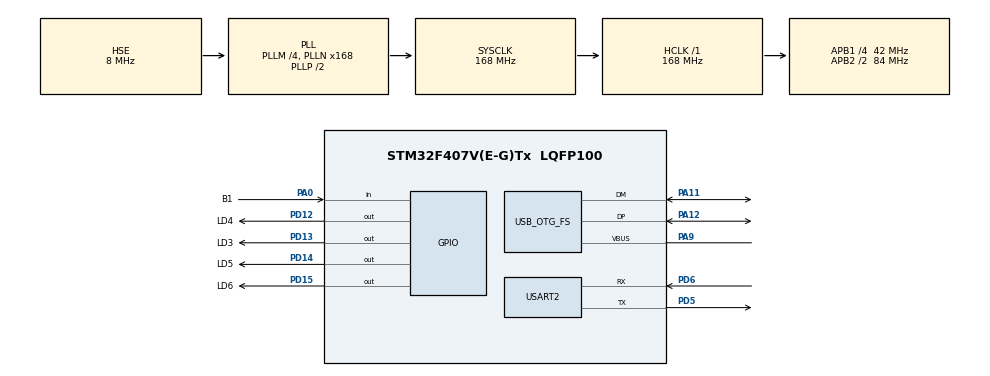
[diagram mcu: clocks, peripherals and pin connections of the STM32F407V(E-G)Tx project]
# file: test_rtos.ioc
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FREERTOS.Tasks01=defaultTask,0,128,StartDefaultTask,Default
Mcu.Family=STM32F4
Mcu.Name=STM32F407V(E-G)Tx
Mcu.Package=LQFP100
NVIC.OTG_FS_IRQn=true\:5\:0\:false\:false\:true\:true
NVIC.PriorityGroup=NVIC_PRIORITYGROUP_4
NVIC.TIM6_DAC_IRQn=true\:0\:0\:false\:false\:true\:false
NVIC.TimeBase=TIM6_DAC_IRQn
NVIC.TimeBaseIP=TIM6
PA0-WKUP.GPIO_Label=B1
PA0-WKUP.Signal=GPIO_Input
PA11.Mode=Device_Only
PA11.Signal=USB_OTG_FS_DM
PA12.Mode=Device_Only
PA12.Signal=USB_OTG_FS_DP
PA9.Mode=Activate_VBUS
PA9.Signal=USB_OTG_FS_VBUS
PD12.GPIO_Label=LD4
PD12.Signal=GPIO_Output
PD13.GPIO_Label=LD3
PD13.Signal=GPIO_Output
PD14.GPIO_Label=LD5
PD14.Signal=GPIO_Output
PD15.GPIO_Label=LD6
PD15.Signal=GPIO_Output
PD5.Mode=Asynchronous
PD5.Signal=USART2_TX
PD6.Mode=Asynchronous
PD6.Signal=USART2_RX
PH0-OSC_IN.Mode=HSE-External-Oscillator
PH0-OSC_IN.Signal=RCC_OSC_IN
PH1-OSC_OUT.Mode=HSE-External-Oscillator
PH1-OSC_OUT.Signal=RCC_OSC_OUT
ProjectManager.HeapSize=0x200
ProjectManager.StackSize=0x400
ProjectManager.TargetToolchain=SW4STM32
RCC.48MHZClocksFreq_Value=48000000
RCC.AHBFreq_Value=168000000
RCC.APB1CLKDivider=RCC_HCLK_DIV4
RCC.APB1Freq_Value=42000000
RCC.APB1TimFreq_Value=84000000
RCC.APB2CLKDivider=RCC_HCLK_DIV2
RCC.APB2Freq_Value=84000000
RCC.APB2TimFreq_Value=168000000
RCC.CortexFreq_Value=168000000
RCC.HCLKFreq_Value=168000000
RCC.HSE_VALUE=8000000
RCC.HSI_VALUE=16000000
RCC.LSE_VALUE=32768
RCC.PLLM=4
RCC.PLLN=168
RCC.PLLQ=7
RCC.SYSCLKFreq_VALUE=168000000
RCC.SYSCLKSource=RCC_SYSCLKSOURCE_PLLCLK
RCC.VCOOutputFreq_Value=336000000
USB_DEVICE.CLASS_NAME-CDC_FS=CDC
USB_DEVICE.CLASS_NAME_FS=CDC
USB_DEVICE.USBD_HandleTypeDef-CDC_FS=hUsbDeviceFS
USB_DEVICE.VirtualMode-CDC_FS=Cdc
USB_DEVICE.VirtualModeFS=Cdc_FS
USB_OTG_FS.VirtualMode=Device_Only
VP_FREERTOS_VS_ENABLE.Mode=Enabled
VP_SYS_VS_tim6.Mode=TIM6
VP_USB_DEVICE_VS_USB_DEVICE_CDC_FS.Mode=CDC_FS
board=test_rtos

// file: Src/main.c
/**
  ******************************************************************************
  * File Name          : main.c
  * Description        : Main program body
  ******************************************************************************
  *
  * Copyright (c) 2017 STMicroelectronics International N.V.
  * All rights reserved.
  *
  * Redistribution and use in source and binary forms, with or without
  * modification, are permitted, provided that the following conditions are met:
  *
  * 1. Redistribution of source code must retain the above copyright notice,
  *    this list of conditions and the following disclaimer.
  * 2. Redistributions in binary form must reproduce the above copyright notice,
  *    this list of conditions and the following disclaimer in the documentation
  *    and/or other materials provided with the distribution.
  * 3. Neither the name of STMicroelectronics nor the names of other
  *    contributors to this software may be used to endorse or promote products
  *    derived from this software without specific written permission.
  * 4. This software, including modifications and/or derivative works of this
  *    software, must execute solely and exclusively on microcontroller or
  *    microprocessor devices manufactured by or for STMicroelectronics.
  * 5. Redistribution and use of this software other than as permitted under
  *    this license is void and will automatically terminate your rights under
  *    this license.
  *
  * THIS SOFTWARE IS PROVIDED BY STMICROELECTRONICS AND CONTRIBUTORS "AS IS"
  * AND ANY EXPRESS, IMPLIED OR STATUTORY WARRANTIES, INCLUDING, BUT NOT
  * LIMITED TO, THE IMPLIED WARRANTIES OF MERCHANTABILITY, FITNESS FOR A
  * PARTICULAR PURPOSE AND NON-INFRINGEMENT OF THIRD PARTY INTELLECTUAL PROPERTY
  * RIGHTS ARE DISCLAIMED TO THE FULLEST EXTENT PERMITTED BY LAW. IN NO EVENT
  * SHALL STMICROELECTRONICS OR CONTRIBUTORS BE LIABLE FOR ANY DIRECT, INDIRECT,
  * INCIDENTAL, SPECIAL, EXEMPLARY, OR CONSEQUENTIAL DAMAGES (INCLUDING, BUT NOT
  * LIMITED TO, PROCUREMENT OF SUBSTITUTE GOODS OR SERVICES; LOSS OF USE, DATA,
  * OR PROFITS; OR BUSINESS INTERRUPTION) HOWEVER CAUSED AND ON ANY THEORY OF
  * LIABILITY, WHETHER IN CONTRACT, STRICT LIABILITY, OR TORT (INCLUDING
  * NEGLIGENCE OR OTHERWISE) ARISING IN ANY WAY OUT OF THE USE OF THIS SOFTWARE,
  * EVEN IF ADVISED OF THE POSSIBILITY OF SUCH DAMAGE.
  *
  ******************************************************************************
  */
#include <mytask.h>
#include "main.h"
#include "stm32f4xx_hal.h"
#include "cmsis_os.h"
#include "usart.h"
#include "gpio.h"

/* USER CODE BEGIN Includes */
#include "retarget.h"
/* USER CODE END Includes */

/* USER CODE BEGIN PV */
/* Private variables ---------------------------------------------------------*/

/* USER CODE END PV */

void SystemClock_Config(void);
void Error_Handler(void);
void MX_FREERTOS_Init(void);

/* USER CODE BEGIN PFP */
/* Private function prototypes -----------------------------------------------*/

/* USER CODE END PFP */

int main(void)
{

  /* MCU Configuration----------------------------------------------------------*/

  /* Reset of all peripherals, Initializes the Flash interface and the Systick. */
  HAL_Init();

  /* Configure the system clock */
  SystemClock_Config();

  /* Initialize all configured peripherals */
  MX_GPIO_Init();
  MX_USART2_UART_Init();

  /* USER CODE BEGIN 2 */
	RetargetInit(&huart2);
  /* USER CODE END 2 */

  /* Call init function for freertos objects (in freertos.c) */
  MX_FREERTOS_Init();

  /* Start scheduler */
  osKernelStart();

  /* We should never get here as control is now taken by the scheduler */

  /* Infinite loop */
  while (1)
  {

  }

}

/** System Clock Configuration
*/
void SystemClock_Config(void)
{

  RCC_OscInitTypeDef RCC_OscInitStruct;
  RCC_ClkInitTypeDef RCC_ClkInitStruct;

    /**Configure the main internal regulator output voltage
    */
  __HAL_RCC_PWR_CLK_ENABLE();

  __HAL_PWR_VOLTAGESCALING_CONFIG(PWR_REGULATOR_VOLTAGE_SCALE1);

    /**Initializes the CPU, AHB and APB busses clocks
    */
  RCC_OscInitStruct.OscillatorType = RCC_OSCILLATORTYPE_HSE;
  RCC_OscInitStruct.HSEState = RCC_HSE_ON;
  RCC_OscInitStruct.PLL.PLLState = RCC_PLL_ON;
  RCC_OscInitStruct.PLL.PLLSource = RCC_PLLSOURCE_HSE;
  RCC_OscInitStruct.PLL.PLLM = 4;
  RCC_OscInitStruct.PLL.PLLN = 168;
  RCC_OscInitStruct.PLL.PLLP = RCC_PLLP_DIV2;
  RCC_OscInitStruct.PLL.PLLQ = 4;
  if (HAL_RCC_OscConfig(&RCC_OscInitStruct) != HAL_OK)
  {
    Error_Handler();
  }

    /**Initializes the CPU, AHB and APB busses clocks
    */
  RCC_ClkInitStruct.ClockType = RCC_CLOCKTYPE_HCLK|RCC_CLOCKTYPE_SYSCLK
                              |RCC_CLOCKTYPE_PCLK1|RCC_CLOCKTYPE_PCLK2;
  RCC_ClkInitStruct.SYSCLKSource = RCC_SYSCLKSOURCE_PLLCLK;
  RCC_ClkInitStruct.AHBCLKDivider = RCC_SYSCLK_DIV1;
  RCC_ClkInitStruct.APB1CLKDivider = RCC_HCLK_DIV4;
  RCC_ClkInitStruct.APB2CLKDivider = RCC_HCLK_DIV2;

  if (HAL_RCC_ClockConfig(&RCC_ClkInitStruct, FLASH_LATENCY_5) != HAL_OK)
  {
    Error_Handler();
  }

    /**Configure the Systick interrupt time
    */
  HAL_SYSTICK_Config(HAL_RCC_GetHCLKFreq()/1000);

    /**Configure the Systick
    */
  HAL_SYSTICK_CLKSourceConfig(SYSTICK_CLKSOURCE_HCLK);

  /* SysTick_IRQn interrupt configuration */
  HAL_NVIC_SetPriority(SysTick_IRQn, 15, 0);
}

void HAL_TIM_PeriodElapsedCallback(TIM_HandleTypeDef *htim)
{
  if (htim->Instance == TIM6) {
    HAL_IncTick();
  }
}

void Error_Handler(void)
{
  while(1)
  {
  }
}

/************************ (C) COPYRIGHT STMicroelectronics *****END OF FILE****/

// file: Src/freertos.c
/**
  ******************************************************************************
  * File Name          : freertos.c
  * Description        : Code for freertos applications
  ******************************************************************************
  *
  * Copyright (c) 2017 STMicroelectronics International N.V.
  * All rights reserved.
  *
  * Redistribution and use in source and binary forms, with or without
  * modification, are permitted, provided that the following conditions are met:
  *
  * 1. Redistribution of source code must retain the above copyright notice,
  *    this list of conditions and the following disclaimer.
  * 2. Redistributions in binary form must reproduce the above copyright notice,
  *    this list of conditions and the following disclaimer in the documentation
  *    and/or other materials provided with the distribution.
  * 3. Neither the name of STMicroelectronics nor the names of other
  *    contributors to this software may be used to endorse or promote products
  *    derived from this software without specific written permission.
  * 4. This software, including modifications and/or derivative works of this
  *    software, must execute solely and exclusively on microcontroller or
  *    microprocessor devices manufactured by or for STMicroelectronics.
  * 5. Redistribution and use of this software other than as permitted under
  *    this license is void and will automatically terminate your rights under
  *    this license.
  *
  * THIS SOFTWARE IS PROVIDED BY STMICROELECTRONICS AND CONTRIBUTORS "AS IS"
  * AND ANY EXPRESS, IMPLIED OR STATUTORY WARRANTIES, INCLUDING, BUT NOT
  * LIMITED TO, THE IMPLIED WARRANTIES OF MERCHANTABILITY, FITNESS FOR A
  * PARTICULAR PURPOSE AND NON-INFRINGEMENT OF THIRD PARTY INTELLECTUAL PROPERTY
  * RIGHTS ARE DISCLAIMED TO THE FULLEST EXTENT PERMITTED BY LAW. IN NO EVENT
  * SHALL STMICROELECTRONICS OR CONTRIBUTORS BE LIABLE FOR ANY DIRECT, INDIRECT,
  * INCIDENTAL, SPECIAL, EXEMPLARY, OR CONSEQUENTIAL DAMAGES (INCLUDING, BUT NOT
  * LIMITED TO, PROCUREMENT OF SUBSTITUTE GOODS OR SERVICES; LOSS OF USE, DATA,
  * OR PROFITS; OR BUSINESS INTERRUPTION) HOWEVER CAUSED AND ON ANY THEORY OF
  * LIABILITY, WHETHER IN CONTRACT, STRICT LIABILITY, OR TORT (INCLUDING
  * NEGLIGENCE OR OTHERWISE) ARISING IN ANY WAY OUT OF THE USE OF THIS SOFTWARE,
  * EVEN IF ADVISED OF THE POSSIBILITY OF SUCH DAMAGE.
  *
  ******************************************************************************
  */

#include <mytask.h>

#include "FreeRTOS.h"
#include "task.h"
#include "cmsis_os.h"

/* USER CODE BEGIN Includes */
#include "stm32f4xx_hal.h"
/* USER CODE END Includes */

osThreadId defaultTaskHandle;

void StartDefaultTask(void const * argument);

void MX_FREERTOS_Init(void); /* (MISRA C 2004 rule 8.1) */

/* Hook prototypes */

/* Init FreeRTOS */

void MX_FREERTOS_Init(void) {

  /* Create the thread(s) */
  /* definition and creation of defaultTask */
  osThreadDef(defaultTask, StartDefaultTask, osPriorityNormal, 0, 128);
  defaultTaskHandle = osThreadCreate(osThread(defaultTask), NULL);

  /* USER CODE BEGIN RTOS_THREADS */
  /* add threads, ... */
  osThreadDef(printTask, StartPrintTask, osPriorityNormal, 0, 128);
  defaultTaskHandle = osThreadCreate(osThread(printTask), NULL);
  /* USER CODE END RTOS_THREADS */

}

/* StartDefaultTask function */
void StartDefaultTask(void const * argument)
{
  /* USER CODE BEGIN StartDefaultTask */
  /* Infinite loop */
  for(;;)
  {
  	HAL_GPIO_TogglePin(LD4_GPIO_Port, LD4_Pin);
    osDelay(100);
  }
  /* USER CODE END StartDefaultTask */
}

/************************ (C) COPYRIGHT STMicroelectronics *****END OF FILE****/
